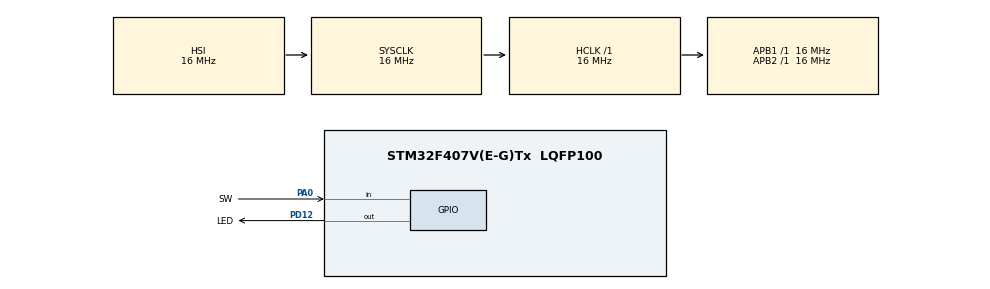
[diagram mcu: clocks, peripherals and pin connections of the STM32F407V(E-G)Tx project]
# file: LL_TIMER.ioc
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Mcu.Family=STM32F4
Mcu.Name=STM32F407V(E-G)Tx
Mcu.Package=LQFP100
NVIC.PriorityGroup=NVIC_PRIORITYGROUP_4
NVIC.TIM6_DAC_IRQn=true\:3\:0\:true\:false\:true\:true\:true\:true
PA0-WKUP.GPIO_Label=SW
PA0-WKUP.Signal=GPIO_Input
PD12.GPIO_Label=LED
PD12.Signal=GPIO_Output
ProjectManager.HeapSize=0x200
ProjectManager.StackSize=0x400
ProjectManager.TargetToolchain=STM32CubeIDE
RCC.48MHZClocksFreq_Value=32000000
RCC.AHBFreq_Value=16000000
RCC.APB1Freq_Value=16000000
RCC.APB1TimFreq_Value=16000000
RCC.APB2Freq_Value=16000000
RCC.APB2TimFreq_Value=16000000
RCC.CortexFreq_Value=16000000
RCC.HCLKFreq_Value=16000000
RCC.HSE_VALUE=25000000
RCC.HSI_VALUE=16000000
RCC.LSE_VALUE=32768
RCC.PLLM=8
RCC.PLLN=64
RCC.SYSCLKFreq_VALUE=16000000
RCC.VCOOutputFreq_Value=128000000
TIM6.Period=10000 - 1
TIM6.Prescaler=16 - 1
VP_TIM6_VS_ClockSourceINT.Mode=Enable_Timer
board=custom

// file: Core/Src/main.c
/* USER CODE BEGIN Header */
/**
  ******************************************************************************
  * @file           : main.c
  * @brief          : Main program body
  ******************************************************************************
  * @attention
  *
  * Copyright (c) 2023 STMicroelectronics.
  * All rights reserved.
  *
  * This software is licensed under terms that can be found in the LICENSE file
  * in the root directory of this software component.
  * If no LICENSE file comes with this software, it is provided AS-IS.
  *
  ******************************************************************************
  */
/* USER CODE END Header */
#include "main.h"
#include "tim.h"
#include "gpio.h"

/* USER CODE BEGIN Includes */
#include "lwbtn.h"
/* USER CODE END Includes */

/* USER CODE BEGIN PTD */
typedef struct{
	GPIO_TypeDef *P;
	uint16_t 	pin;
}Button_Phy_t;
/* USER CODE END PTD */

/* USER CODE BEGIN PV */
Button_Phy_t sw1 = {
		.P = SW_GPIO_Port,
		.pin = SW_Pin
};
Button_Phy_t sw2 = {
		.P = SW_GPIO_Port,
		.pin = SW_Pin
};
lwbtn_btn_t btns[] = {
		{.arg = (void*)&sw1},
		{.arg = (void*)&sw2}
};
/* USER CODE END PV */

void SystemClock_Config(void);
/* USER CODE BEGIN PFP */
static uint8_t prv_btn_get_state(struct lwbtn* lw, struct lwbtn_btn* btn);

static void prv_btn_event(struct lwbtn* lw, struct lwbtn_btn* btn, lwbtn_evt_t evt){
	switch(evt){
	case LWBTN_EVT_ONPRESS:

		break;
	case LWBTN_EVT_ONRELEASE:

		break;
	case LWBTN_EVT_ONCLICK:

		break;
	}
}
/* USER CODE END PFP */

int main(void)
{

  /* MCU Configuration--------------------------------------------------------*/

  /* Reset of all peripherals, Initializes the Flash interface and the Systick. */
  HAL_Init();

  /* Configure the system clock */
  SystemClock_Config();

  /* Initialize all configured peripherals */
  MX_GPIO_Init();
  MX_TIM6_Init();
  /* USER CODE BEGIN 2 */
  //LL_TIM_EnableIT_UPDATE(TIM6);
  TIM6->DIER |= TIM_DIER_UIE;
  //LL_TIM_EnableCounter(TIM6);
  TIM6->CR1 |= TIM_CR1_CEN;

  lwbtn_init(btns, 2, prv_btn_get_state, prv_btn_event);

  /* USER CODE END 2 */

  /* Infinite loop */
  while (1)
  {

  }
}

void SystemClock_Config(void)
{
  RCC_OscInitTypeDef RCC_OscInitStruct = {0};
  RCC_ClkInitTypeDef RCC_ClkInitStruct = {0};

  /** Configure the main internal regulator output voltage
  */
  __HAL_RCC_PWR_CLK_ENABLE();
  __HAL_PWR_VOLTAGESCALING_CONFIG(PWR_REGULATOR_VOLTAGE_SCALE1);

  /** Initializes the RCC Oscillators according to the specified parameters
  * in the RCC_OscInitTypeDef structure.
  */
  RCC_OscInitStruct.OscillatorType = RCC_OSCILLATORTYPE_HSI;
  RCC_OscInitStruct.HSIState = RCC_HSI_ON;
  RCC_OscInitStruct.HSICalibrationValue = RCC_HSICALIBRATION_DEFAULT;
  RCC_OscInitStruct.PLL.PLLState = RCC_PLL_NONE;
  if (HAL_RCC_OscConfig(&RCC_OscInitStruct) != HAL_OK)
  {
    Error_Handler();
  }

  /** Initializes the CPU, AHB and APB buses clocks
  */
  RCC_ClkInitStruct.ClockType = RCC_CLOCKTYPE_HCLK|RCC_CLOCKTYPE_SYSCLK
                              |RCC_CLOCKTYPE_PCLK1|RCC_CLOCKTYPE_PCLK2;
  RCC_ClkInitStruct.SYSCLKSource = RCC_SYSCLKSOURCE_HSI;
  RCC_ClkInitStruct.AHBCLKDivider = RCC_SYSCLK_DIV1;
  RCC_ClkInitStruct.APB1CLKDivider = RCC_HCLK_DIV1;
  RCC_ClkInitStruct.APB2CLKDivider = RCC_HCLK_DIV1;

  if (HAL_RCC_ClockConfig(&RCC_ClkInitStruct, FLASH_LATENCY_0) != HAL_OK)
  {
    Error_Handler();
  }
}

/* USER CODE BEGIN 4 */
static uint8_t prv_btn_get_state(struct lwbtn* lw, struct lwbtn_btn* btn){
	Button_Phy_t *b = (Button_Phy_t*)btn->arg;
	uint8_t state = 0;
//	switch(b->pin){
//	case GPIO_PIN_0
//		pin = 0;
//	}
	if(b == &sw1){
		state = (HAL_GPIO_ReadPin(b->P, b->pin) == GPIO_PIN_SET) ? 0 : 1;
	}else if(b == &sw2){
		state = (HAL_GPIO_ReadPin(b->P, b->pin) == GPIO_PIN_RESET) ? 0 : 1;
	}
	return state;
}
/* USER CODE END 4 */

void Error_Handler(void)
{
  __disable_irq();
  while (1)
  {
  }
}
